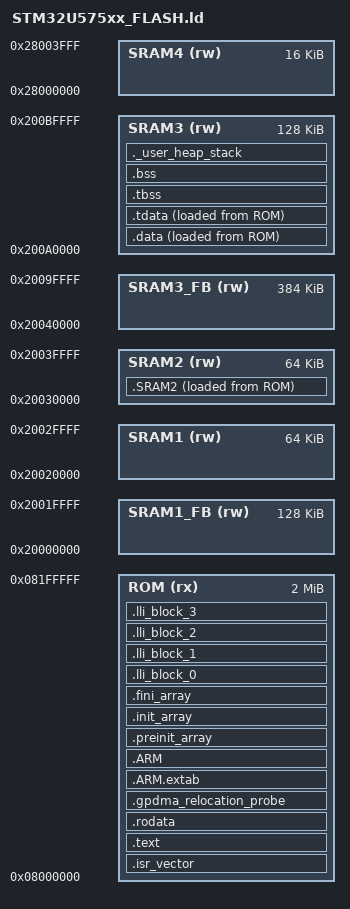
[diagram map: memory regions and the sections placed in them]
/*
******************************************************************************
**
**  File        : LinkerScript.ld
**
**  Author      : Auto-generated by STM32CubeIDE (Customized for SRAM & GPDMA LLI)
**
**  Abstract    : Linker script for STM32U575xx Device
**
*****************************************************************************
*/

/* Entry Point */
ENTRY(Reset_Handler)

/* Memories definition */
MEMORY
{
  ROM       (rx)  : ORIGIN = 0x08000000, LENGTH = 2048K
  
  /* --- 1. 手動固定エリア（フレームバッファ用：自動配置しない） --- */
  SRAM1_FB  (rw) : ORIGIN = 0x20000000, LENGTH = 128K
  SRAM3_FB  (rw) : ORIGIN = 0x20040000, LENGTH = 384K

  /* --- 2. 自動配置用エリア --- */
  SRAM1     (rw) : ORIGIN = 0x20020000, LENGTH = 64K
  SRAM2     (rw) : ORIGIN = 0x20030000, LENGTH = 64K
  SRAM3     (rw) : ORIGIN = 0x200A0000, LENGTH = 128K
  
  SRAM4     (rw) : ORIGIN = 0x28000000, LENGTH = 16K
}

/* Highest address of the user mode stack (SRAM3の末尾に配置) */
_estack = ORIGIN(SRAM3) + LENGTH(SRAM3);

_Min_Heap_Size = 0x400;      /* required amount of heap */
_Min_Stack_Size = 0x2000;    /* required amount of stack */

/* Sections */
SECTIONS
{
  /* The startup code into "ROM" Rom type memory */
  .isr_vector :
  {
    . = ALIGN(8);
    KEEP(*(.isr_vector)) /* Startup code */
    . = ALIGN(8);
  } >ROM

  /* The program code and other data into "ROM" Rom type memory */
  .text :
  {
    . = ALIGN(8);
    *(.text)            /* .text sections (code) */
    *(.text*)           /* .text* sections (code) */
    *(.glue_7)          /* glue arm to thumb code */
    *(.glue_7t)         /* glue thumb to arm code */
    *(.eh_frame)

    KEEP (*(.init))
    KEEP (*(.fini))

    . = ALIGN(8);
    _etext = .;         /* define a global symbols at end of code */
  } >ROM

  /* Constant data into "ROM" Rom type memory */
  .rodata :
  {
    . = ALIGN(8);
    *(.rodata)          /* .rodata sections (constants, strings, etc.) */
    *(.rodata*)         /* .rodata* sections (constants, strings, etc.) */
    . = ALIGN(8);
  } >ROM

  /* Retain the static relocation probe so its completed image can be inspected. */
  .gpdma_relocation_probe (READONLY) :
  {
    . = ALIGN(4);
    KEEP(*(.gpdma_relocation_probe))
    . = ALIGN(4);
  } >ROM

  .ARM.extab (READONLY) : 
  {
    . = ALIGN(8);
    *(.ARM.extab* .gnu.linkonce.armextab.*)
    . = ALIGN(8);
  } >ROM
  
  .ARM (READONLY) : 
  {
    . = ALIGN(8);
    __exidx_start = .;
    *(.ARM.exidx*)
    __exidx_end = .;
    . = ALIGN(8);
  } >ROM

  .preinit_array (READONLY) : 
  {
    . = ALIGN(8);
    PROVIDE_HIDDEN (__preinit_array_start = .);
    KEEP (*(.preinit_array*))
    PROVIDE_HIDDEN (__preinit_array_end = .);
    . = ALIGN(8);
  } >ROM
  
  .init_array (READONLY) : 
  {
    . = ALIGN(8);
    PROVIDE_HIDDEN (__init_array_start = .);
    KEEP (*(SORT(.init_array.*)))
    KEEP (*(.init_array*))
    PROVIDE_HIDDEN (__init_array_end = .);
    . = ALIGN(8);
  } >ROM
  
  .fini_array (READONLY) : 
  {
    . = ALIGN(8);
    PROVIDE_HIDDEN (__fini_array_start = .);
    KEEP (*(SORT(.fini_array.*)))
    KEEP (*(.fini_array*))
    PROVIDE_HIDDEN (__fini_array_end = .);
    . = ALIGN(8);
  } >ROM


  /* --- GPDMA LLI用 Flashブロック 0〜3 (64KB境界アライメント ＆ 境界またぎ防止) --- */
  
  .lli_block_0 ALIGN(0x10000) :
  {
    _lli0_start = .;
    KEEP(*(.lli_data_0*))
    . = ALIGN(4);
    _lli0_end = .;
  } > ROM
  ASSERT((ADDR(.lli_block_0) & 0xFFFF) == 0, "Error: lli_block_0 is not 64KB aligned!")
  ASSERT(((_lli0_end - _lli0_start) <= 0x10000), "Error: lli_block_0 exceeds 64KB boundary!")

  .lli_block_1 ALIGN(0x10000) : 
  {
    _lli1_start = .;
    KEEP(*(.lli_data_1*))
    . = ALIGN(4);
    _lli1_end = .;
  } > ROM
  ASSERT((ADDR(.lli_block_1) & 0xFFFF) == 0, "Error: lli_block_1 is not 64KB aligned!")
  ASSERT(((_lli1_end - _lli1_start) <= 0x10000), "Error: lli_block_1 exceeds 0x10000!")

  .lli_block_2 ALIGN(0x10000) : 
  {
    _lli2_start = .;
    KEEP(*(.lli_data_2*))
    . = ALIGN(4);
    _lli2_end = .;
  } > ROM
  ASSERT((ADDR(.lli_block_2) & 0xFFFF) == 0, "Error: lli_block_2 is not 64KB aligned!")
  ASSERT(((_lli2_end - _lli2_start) <= 0x10000), "Error: lli_block_2 exceeds 0x10000!")

  .lli_block_3 ALIGN(0x10000) : 
  {
    _lli3_start = .;
    KEEP(*(.lli_data_3*))
    . = ALIGN(4);
    _lli3_end = .;
  } > ROM
  ASSERT((ADDR(.lli_block_3) & 0xFFFF) == 0, "Error: lli_block_3 is not 64KB aligned!")
  ASSERT(((_lli3_end - _lli3_start) <= 0x10000), "Error: lli_block_3 exceeds 0x10000!")

  /* -----------------------------------------------------------------------
   * Writable GPDMA LLI ROOT in SRAM2
   *
   * SRAM2:
   *   ORIGIN = 0x20030000
   *   LENGTH = 64 KiB
   *
   * The entire region corresponds to one CLBAR address space.
   * Initial contents are stored in ROM and copied to SRAM2 at startup.
   * ----------------------------------------------------------------------- */
  .SRAM2 :
  {
    . = ALIGN(8);

    __sram2_start__ = .;

    KEEP(*(.SRAM2))
    KEEP(*(.SRAM2.*))

    . = ALIGN(8);

    __sram2_end__ = .;
  } > SRAM2 AT > ROM

  __sram2_load__ = LOADADDR(.SRAM2);
  __sram2_size__ = SIZEOF(.SRAM2);

  ASSERT(
    (ADDR(.SRAM2) & 0xFFFF) == 0,
    "Error: .SRAM2 is not aligned to a 64 KiB CLBAR boundary!"
  )

  ASSERT(
    SIZEOF(.SRAM2) <= LENGTH(SRAM2),
    "Error: .SRAM2 exceeds the SRAM2 region!"
  )

  ASSERT(
    (ADDR(.SRAM2) + SIZEOF(.SRAM2))
      <= (ORIGIN(SRAM2) + LENGTH(SRAM2)),
    "Error: .SRAM2 crosses the SRAM2 boundary!"
  )

  ASSERT(
    (__sram2_size__ & 3) == 0,
    "Error: .SRAM2 size is not a multiple of 4!"
  )

  ASSERT(
    (__sram2_start__ & 3) == 0,
    "Error: .SRAM2 start is not 4-byte aligned!"
  )

  ASSERT(
    (__sram2_load__ & 3) == 0,
    "Error: .SRAM2 load address is not 4-byte aligned!"
  )


  /*
   * ==========================================================================
   * Initialized SRAM3 data
   *
   * This is the original initialized-data region copied by Reset_Handler:
   *
   *     _sidata -> _sdata .. _edata
   *
   * Keep this region separate from .SRAM2 for this experiment.
   * ==========================================================================
   */

  /* Start address of the SRAM3 initialized-data image in ROM. */
  _sidata = LOADADDR(.data);

  /* Initialized ordinary data in SRAM3. */
  .data :
  {
    . = ALIGN(8);

    _sdata = .;

    *(.data)
    *(.data*)

    *(.ramfunc)
    *(.ramfunc*)

    . = ALIGN(8);
  } > SRAM3 AT> ROM

  /* Initialized TLS data, contiguous with .data in SRAM3 and ROM. */
  .tdata : ALIGN(4)
  {
    *(.tdata .tdata.* .gnu.linkonce.td.*)

    . = ALIGN(4);

    _edata = .;

    PROVIDE(__data_end = .);
    PROVIDE(__tdata_end = .);
  } > SRAM3 AT> ROM

  PROVIDE(__tdata_start = ADDR(.tdata));
  PROVIDE(__tdata_size = __tdata_end - __tdata_start);

  PROVIDE(__data_start = ADDR(.data));
  PROVIDE(__data_size = __data_end - __data_start);

  PROVIDE(__tdata_source = LOADADDR(.tdata));
  PROVIDE(__tdata_source_end =
          LOADADDR(.tdata) + SIZEOF(.tdata));
  PROVIDE(__tdata_source_size =
          __tdata_source_end - __tdata_source);

  PROVIDE(__data_source = LOADADDR(.data));
  PROVIDE(__data_source_end = __tdata_source_end);
  PROVIDE(__data_source_size =
          __data_source_end - __data_source);


  /* Uninitialized data section (.tbss) */
  .tbss (NOLOAD) : ALIGN(4)
  {
    _sbss = .;          /* スタートアップが参照するBSS開始シンボル */
    __bss_start__ = _sbss;
    *(.tbss .tbss.*)
    . = ALIGN(4);
    PROVIDE( __tbss_end = . );
  } >SRAM3

  PROVIDE( __tbss_start = ADDR(.tbss) );
  PROVIDE( __tbss_size = __tbss_end - __tbss_start );

  /* Uninitialized data section (.bss) */
  .bss (NOLOAD) : ALIGN(4)
  {
    *(.bss)
    *(.bss*)
    *(COMMON)
    . = ALIGN(8);
    _ebss = .;          /* スタートアップが参照するBSS終了シンボル */
    __bss_end__ = _ebss;
    PROVIDE( __bss_end = . );
  } >SRAM3

  PROVIDE( __bss_start = __tbss_start );
  PROVIDE( __bss_size = __bss_end - __bss_start );

  /* User_heap_stack section, used to check that there is enough RAM left */
  ._user_heap_stack (NOLOAD) :
  {
    . = ALIGN(8);
    PROVIDE ( end = . );
    PROVIDE ( _end = . );  /* sysmem.c が参照する終了シンボル */
    . = . + _Min_Heap_Size;
    . = . + _Min_Stack_Size;
    . = ALIGN(8);
  } >SRAM3

  /* Remove information from the compiler libraries */
  /DISCARD/ :
  {
    libc.a:* ( * )
    libm.a:* ( * )
    libgcc.a:* ( * )
  }

  .ARM.attributes 0 : { *(.ARM.attributes) }
}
